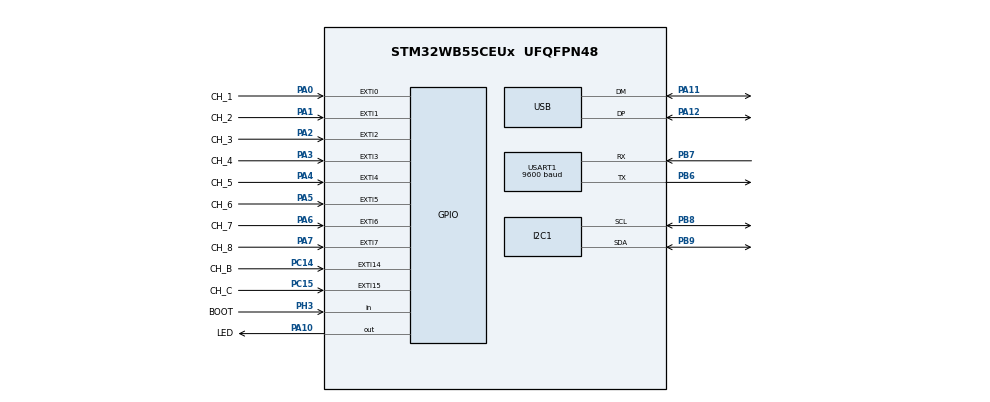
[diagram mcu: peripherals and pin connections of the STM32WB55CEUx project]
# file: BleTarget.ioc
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I2C1.OwnAddress=2
I2C1.Timing=0x10707DBC
Mcu.Family=STM32WB
Mcu.Name=STM32WB55CEUx
Mcu.Package=UFQFPN48
NVIC.EXTI0_IRQn=true\:0\:0\:false\:false\:true\:true\:true\:true
NVIC.EXTI15_10_IRQn=true\:0\:0\:true\:false\:true\:true\:true\:true
NVIC.EXTI1_IRQn=true\:0\:0\:false\:false\:true\:true\:true\:true
NVIC.EXTI2_IRQn=true\:0\:0\:false\:false\:true\:true\:true\:true
NVIC.EXTI3_IRQn=true\:0\:0\:false\:false\:true\:true\:true\:true
NVIC.EXTI4_IRQn=true\:0\:0\:false\:false\:true\:true\:true\:true
NVIC.EXTI9_5_IRQn=true\:0\:0\:false\:false\:true\:true\:true\:true
NVIC.HSEM_IRQn=true\:1\:0\:true\:false\:true\:false\:true\:true
NVIC.I2C1_ER_IRQn=true\:1\:0\:true\:false\:true\:true\:true\:true
NVIC.I2C1_EV_IRQn=true\:1\:0\:true\:false\:true\:true\:true\:true
NVIC.IPCC_C1_RX_IRQn=true\:1\:0\:true\:false\:true\:true\:true\:true
NVIC.IPCC_C1_TX_IRQn=true\:1\:0\:true\:false\:true\:true\:true\:true
NVIC.PriorityGroup=NVIC_PRIORITYGROUP_4
NVIC.TIM1_TRG_COM_TIM17_IRQn=true\:1\:0\:true\:false\:true\:true\:true\:true
NVIC.TIM1_UP_TIM16_IRQn=true\:15\:0\:false\:false\:true\:true\:true\:true
NVIC.TIM2_IRQn=true\:1\:0\:true\:false\:true\:true\:true\:true
NVIC.USART1_IRQn=true\:1\:0\:true\:false\:true\:true\:true\:true
NVIC.USB_LP_IRQn=true\:1\:0\:true\:false\:true\:false\:true\:true
OSC_IN.Mode=HSE-External-Oscillator
OSC_IN.Signal=RCC_OSC_IN
OSC_OUT.Mode=HSE-External-Oscillator
OSC_OUT.Signal=RCC_OSC_OUT
PA0.GPIO_Label=CH_1
PA0.Signal=GPXTI0
PA1.GPIO_Label=CH_2
PA1.Signal=GPXTI1
PA10.GPIO_Label=LED
PA10.GPIO_ModeDefaultOutputPP=GPIO_MODE_OUTPUT_OD
PA10.GPIO_PuPd=GPIO_NOPULL
PA10.GPIO_Speed=GPIO_SPEED_FREQ_MEDIUM
PA10.PinState=GPIO_PIN_SET
PA10.Signal=GPIO_Output
PA11.Mode=Device
PA11.Signal=USB_DM
PA12.Mode=Device
PA12.Signal=USB_DP
PA13.Mode=Trace_Asynchronous_SW
PA13.Signal=SYS_JTMS-SWDIO
PA14.Mode=Trace_Asynchronous_SW
PA14.Signal=SYS_JTCK-SWCLK
PA2.GPIO_Label=CH_3
PA2.Signal=GPXTI2
PA3.GPIO_Label=CH_4
PA3.Signal=GPXTI3
PA4.GPIO_Label=CH_5
PA4.Signal=GPXTI4
PA5.GPIO_Label=CH_6
PA5.Signal=GPXTI5
PA6.GPIO_Label=CH_7
PA6.Signal=GPXTI6
PA7.GPIO_Label=CH_8
PA7.Signal=GPXTI7
PB3.Mode=Trace_Asynchronous_SW
PB3.Signal=SYS_JTDO-SWO
PB6.Mode=Asynchronous
PB6.Signal=USART1_TX
PB7.Mode=Asynchronous
PB7.Signal=USART1_RX
PB8.Mode=I2C
PB8.Signal=I2C1_SCL
PB9.Mode=I2C
PB9.Signal=I2C1_SDA
PC14-OSC32_IN.GPIO_Label=CH_B
PC14-OSC32_IN.Signal=GPXTI14
PC15-OSC32_OUT.GPIO_Label=CH_C
PC15-OSC32_OUT.Signal=GPXTI15
PH3-BOOT0.GPIO_Label=BOOT
PH3-BOOT0.Signal=GPIO_Input
ProjectManager.HeapSize=0x200
ProjectManager.StackSize=0x400
ProjectManager.TargetToolchain=STM32CubeIDE
RCC.ADCFreq_Value=48000000
RCC.AHB2CLKDivider=RCC_SYSCLK_DIV2
RCC.AHBFreq_Value=64000000
RCC.APB1Freq_Value=64000000
RCC.APB1TimFreq_Value=64000000
RCC.APB2Freq_Value=64000000
RCC.APB2TimFreq_Value=64000000
RCC.APB3Freq_Value=16000000
RCC.CortexFreq_Value=64000000
RCC.HCLKFreq_Value=64000000
RCC.HSE_VALUE=32000000
RCC.HSI48_VALUE=48000000
RCC.HSI_VALUE=16000000
RCC.LSE_VALUE=32768
RCC.PLLN=32
RCC.PLLSAI1N=24
RCC.SYSCLKFreq_VALUE=64000000
RCC.SYSCLKSource=RCC_SYSCLKSOURCE_PLLCLK
RCC.USBFreq_Value=48000000
RCC.VCOOutputFreq_Value=128000000
RF1.Mode=RF1_Activate
RF1.Signal=RF_RF1
STM32_WPAN.AD_TYPE_COMPLETE_LOCAL_NAME=BLEtarget
STM32_WPAN.AD_TYPE_COMPLETE_LOCAL_NAME_LENGTH=10
STM32_WPAN.CFG_RTC_ASYNCH_PRESCALER=127
STM32_WPAN.CFG_RTC_SYNCH_PRESCALER=7812
STM32_WPAN.CFG_TX_POWER=(0x1F) /* 6dBm */
STM32_WPAN.CUSTOM_P2P_SERVER=Disabled
STM32_WPAN.CUSTOM_TEMPLATE=Enabled
STM32_WPAN.INCLUDE_AD_TYPE_COMPLETE_LOCAL_NAME=1
STM32_WPAN.NUMBER_OF_SERVICES=1
STM32_WPAN.PAIRING_PARAMETERS=OFF
STM32_WPAN.SERVICE1_CHAR1_GATT_NOTIFY_ATTRIBUTE_WRITE=\ 
STM32_WPAN.SERVICE1_CHAR1_GATT_NOTIFY_READ_REQ_AND_WAIT_FOR_APPL_RESP=\ 
STM32_WPAN.SERVICE1_CHAR1_GATT_NOTIFY_WRITE_REQ_AND_WAIT_FOR_APPL_RESP=\ 
STM32_WPAN.SERVICE1_CHAR1_LONG_NAME=X_position
STM32_WPAN.SERVICE1_CHAR1_PROP_NOTIFY=CHAR_PROP_NOTIFY
STM32_WPAN.SERVICE1_CHAR1_PROP_READ=CHAR_PROP_READ
STM32_WPAN.SERVICE1_CHAR1_SHORT_NAME=X
STM32_WPAN.SERVICE1_CHAR1_UUID=00 11
STM32_WPAN.SERVICE1_CHAR1_UUID_128_INPUT_TYPE=0
STM32_WPAN.SERVICE1_CHAR2_GATT_NOTIFY_ATTRIBUTE_WRITE=\ 
STM32_WPAN.SERVICE1_CHAR2_GATT_NOTIFY_READ_REQ_AND_WAIT_FOR_APPL_RESP=\ 
STM32_WPAN.SERVICE1_CHAR2_GATT_NOTIFY_WRITE_REQ_AND_WAIT_FOR_APPL_RESP=\ 
STM32_WPAN.SERVICE1_CHAR2_LONG_NAME=Y_position
STM32_WPAN.SERVICE1_CHAR2_PROP_NOTIFY=CHAR_PROP_NOTIFY
STM32_WPAN.SERVICE1_CHAR2_PROP_READ=CHAR_PROP_READ
STM32_WPAN.SERVICE1_CHAR2_SHORT_NAME=Y
STM32_WPAN.SERVICE1_CHAR2_UUID=00 12
STM32_WPAN.SERVICE1_LONG_NAME=Score
STM32_WPAN.SERVICE1_NUMBER_OF_CHARACTERISTICS=2
STM32_WPAN.SERVICE1_SHORT_NAME=Score
STM32_WPAN.SERVICE1_UUID=00 10
TIM16.Period=5999
TIM16.Prescaler=6399
TIM17.Period=20000
TIM17.Prescaler=6399
TIM2.Period=640000
USART1.BaudRate=9600
USART1.VirtualMode-Asynchronous=VM_ASYNC
USB_DEVICE.CLASS_NAME_FS=CDC
USB_DEVICE.PRODUCT_STRING_CDC_FS=STM32 Virtual ComPort
USB_DEVICE.USBD_MAX_NUM_CONFIGURATION=1
USB_DEVICE.USBD_MAX_NUM_INTERFACES=1
USB_DEVICE.VirtualMode=Cdc
USB_DEVICE.VirtualModeFS=Cdc_FS
VP_HSEM_VS_HSEM.Mode=HSEM_Activate
VP_IPCC_VS_IPCC.Mode=IPCC_Activate
VP_MEMORYMAP_VS_MEMORYMAP.Mode=CurAppReg
VP_RTC_VS_RTC_Activate.Mode=RTC_Enabled
VP_SEQUENCER_VS_SEQUENCER.Mode=SEQUENCER_Enabled
VP_STM32_WPAN_VS_BLE_HOST.Mode=STM32_WPAN_Enabled
VP_TIM16_VS_ClockSourceINT.Mode=Enable_Timer
VP_TIM17_VS_ClockSourceINT.Mode=Enable_Timer
VP_TIM2_VS_ClockSourceINT.Mode=Internal
VP_TINY_LPM_VS_TINY_LPM.Mode=TINY_LPM_Enabled
VP_USB_DEVICE_VS_USB_DEVICE_CDC_FS.Mode=CDC_FS
board=custom

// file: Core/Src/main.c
/* USER CODE BEGIN Header */
/**
  ******************************************************************************
  * @file           : main.c
  * @brief          : Main program body
  ******************************************************************************
  * @attention
  *
  * Copyright (c) 2024 STMicroelectronics.
  * All rights reserved.
  *
  * This software is licensed under terms that can be found in the LICENSE file
  * in the root directory of this software component.
  * If no LICENSE file comes with this software, it is provided AS-IS.
  *
  ******************************************************************************
  */
/* USER CODE END Header */
#include "main.h"
#include "usb_device.h"

/* USER CODE BEGIN Includes */
#include "app.h"
/* USER CODE END Includes */

I2C_HandleTypeDef hi2c1;

IPCC_HandleTypeDef hipcc;

RTC_HandleTypeDef hrtc;

UART_HandleTypeDef huart1;

void SystemClock_Config(void);
void PeriphCommonClock_Config(void);
static void MX_GPIO_Init(void);
static void MX_I2C1_Init(void);
static void MX_IPCC_Init(void);
static void MX_RTC_Init(void);
static void MX_USART1_UART_Init(void);
static void MX_TIM16_Init(void);
static void MX_TIM2_Init(void);
static void MX_TIM17_Init(void);
static void MX_RF_Init(void);

int main(void)
{

  /* USER CODE BEGIN 1 */
  //TIM_TypeDef *comTimer;   // 1ms timer used as timeout for com with other axis.

  /* USER CODE END 1 */

  /* MCU Configuration--------------------------------------------------------*/

  /* Reset of all peripherals, Initializes the Flash interface and the Systick. */
  HAL_Init();
  /* Config code for STM32_WPAN (HSE Tuning must be done before system clock configuration) */
  MX_APPE_Config();

  /* Configure the system clock */
  SystemClock_Config();

/* Configure the peripherals common clocks */
  PeriphCommonClock_Config();

  /* IPCC initialisation */
  MX_IPCC_Init();

  /* Initialize all configured peripherals */
  MX_GPIO_Init();
  MX_I2C1_Init();
  MX_RTC_Init();
  MX_USART1_UART_Init();
  MX_USB_Device_Init();
  MX_TIM16_Init();
  MX_TIM2_Init();
  MX_TIM17_Init();
  MX_RF_Init();
  /* USER CODE BEGIN 2 */
  app_init(&hi2c1, &huart1);
  /* USER CODE END 2 */

  /* Init code for STM32_WPAN */
  MX_APPE_Init();

  /* Infinite loop */
  while (1)
  {
    MX_APPE_Process();

    /* USER CODE BEGIN 3 */
    taskCyclic();
  }
  /* USER CODE END 3 */
}

void SystemClock_Config(void)
{
  RCC_OscInitTypeDef RCC_OscInitStruct = {0};
  RCC_ClkInitTypeDef RCC_ClkInitStruct = {0};

  /** Configure the main internal regulator output voltage
  */
  __HAL_PWR_VOLTAGESCALING_CONFIG(PWR_REGULATOR_VOLTAGE_SCALE1);

  /** Initializes the RCC Oscillators according to the specified parameters
  * in the RCC_OscInitTypeDef structure.
  */
  RCC_OscInitStruct.OscillatorType = RCC_OSCILLATORTYPE_HSI|RCC_OSCILLATORTYPE_LSI1
                              |RCC_OSCILLATORTYPE_HSE|RCC_OSCILLATORTYPE_LSE
                              |RCC_OSCILLATORTYPE_MSI;
  RCC_OscInitStruct.HSEState = RCC_HSE_ON;
  RCC_OscInitStruct.LSEState = RCC_LSE_OFF;
  RCC_OscInitStruct.HSIState = RCC_HSI_ON;
  RCC_OscInitStruct.MSIState = RCC_MSI_ON;
  RCC_OscInitStruct.HSICalibrationValue = RCC_HSICALIBRATION_DEFAULT;
  RCC_OscInitStruct.MSICalibrationValue = RCC_MSICALIBRATION_DEFAULT;
  RCC_OscInitStruct.MSIClockRange = RCC_MSIRANGE_6;
  RCC_OscInitStruct.LSIState = RCC_LSI_ON;
  RCC_OscInitStruct.PLL.PLLState = RCC_PLL_ON;
  RCC_OscInitStruct.PLL.PLLSource = RCC_PLLSOURCE_MSI;
  RCC_OscInitStruct.PLL.PLLM = RCC_PLLM_DIV1;
  RCC_OscInitStruct.PLL.PLLN = 32;
  RCC_OscInitStruct.PLL.PLLP = RCC_PLLP_DIV2;
  RCC_OscInitStruct.PLL.PLLR = RCC_PLLR_DIV2;
  RCC_OscInitStruct.PLL.PLLQ = RCC_PLLQ_DIV2;
  if (HAL_RCC_OscConfig(&RCC_OscInitStruct) != HAL_OK)
  {
    Error_Handler();
  }

  /** Configure the SYSCLKSource, HCLK, PCLK1 and PCLK2 clocks dividers
  */
  RCC_ClkInitStruct.ClockType = RCC_CLOCKTYPE_HCLK4|RCC_CLOCKTYPE_HCLK2
                              |RCC_CLOCKTYPE_HCLK|RCC_CLOCKTYPE_SYSCLK
                              |RCC_CLOCKTYPE_PCLK1|RCC_CLOCKTYPE_PCLK2;
  RCC_ClkInitStruct.SYSCLKSource = RCC_SYSCLKSOURCE_PLLCLK;
  RCC_ClkInitStruct.AHBCLKDivider = RCC_SYSCLK_DIV1;
  RCC_ClkInitStruct.APB1CLKDivider = RCC_HCLK_DIV1;
  RCC_ClkInitStruct.APB2CLKDivider = RCC_HCLK_DIV1;
  RCC_ClkInitStruct.AHBCLK2Divider = RCC_SYSCLK_DIV2;
  RCC_ClkInitStruct.AHBCLK4Divider = RCC_SYSCLK_DIV1;

  if (HAL_RCC_ClockConfig(&RCC_ClkInitStruct, FLASH_LATENCY_3) != HAL_OK)
  {
    Error_Handler();
  }

  /** Enable MSI Auto calibration
  */
  HAL_RCCEx_EnableMSIPLLMode();
}

void PeriphCommonClock_Config(void)
{
  RCC_PeriphCLKInitTypeDef PeriphClkInitStruct = {0};

  /** Initializes the peripherals clock
  */
  PeriphClkInitStruct.PeriphClockSelection = RCC_PERIPHCLK_SMPS|RCC_PERIPHCLK_RFWAKEUP;
  PeriphClkInitStruct.RFWakeUpClockSelection = RCC_RFWKPCLKSOURCE_HSE_DIV1024;
  PeriphClkInitStruct.SmpsClockSelection = RCC_SMPSCLKSOURCE_HSI;
  PeriphClkInitStruct.SmpsDivSelection = RCC_SMPSCLKDIV_RANGE1;

  if (HAL_RCCEx_PeriphCLKConfig(&PeriphClkInitStruct) != HAL_OK)
  {
    Error_Handler();
  }
  /* USER CODE BEGIN Smps */
  LL_HSEM_1StepLock( HSEM, 5 ); // Fix to make USB work with BLE.
  /* USER CODE END Smps */
}

static void MX_I2C1_Init(void)
{

  hi2c1.Instance = I2C1;
  hi2c1.Init.Timing = 0x10707DBC;
  hi2c1.Init.OwnAddress1 = 4;
  hi2c1.Init.AddressingMode = I2C_ADDRESSINGMODE_7BIT;
  hi2c1.Init.DualAddressMode = I2C_DUALADDRESS_DISABLE;
  hi2c1.Init.OwnAddress2 = 0;
  hi2c1.Init.OwnAddress2Masks = I2C_OA2_NOMASK;
  hi2c1.Init.GeneralCallMode = I2C_GENERALCALL_DISABLE;
  hi2c1.Init.NoStretchMode = I2C_NOSTRETCH_DISABLE;
  if (HAL_I2C_Init(&hi2c1) != HAL_OK)
  {
    Error_Handler();
  }

  /** Configure Analogue filter
  */
  if (HAL_I2CEx_ConfigAnalogFilter(&hi2c1, I2C_ANALOGFILTER_ENABLE) != HAL_OK)
  {
    Error_Handler();
  }

  /** Configure Digital filter
  */
  if (HAL_I2CEx_ConfigDigitalFilter(&hi2c1, 0) != HAL_OK)
  {
    Error_Handler();
  }

}

static void MX_IPCC_Init(void)
{

  hipcc.Instance = IPCC;
  if (HAL_IPCC_Init(&hipcc) != HAL_OK)
  {
    Error_Handler();
  }

}

static void MX_RF_Init(void)
{

}

static void MX_RTC_Init(void)
{

  /** Initialize RTC Only
  */
  hrtc.Instance = RTC;
  hrtc.Init.HourFormat = RTC_HOURFORMAT_24;
  hrtc.Init.AsynchPrediv = CFG_RTC_ASYNCH_PRESCALER;
  hrtc.Init.SynchPrediv = CFG_RTC_SYNCH_PRESCALER;
  hrtc.Init.OutPut = RTC_OUTPUT_DISABLE;
  hrtc.Init.OutPutPolarity = RTC_OUTPUT_POLARITY_HIGH;
  hrtc.Init.OutPutType = RTC_OUTPUT_TYPE_OPENDRAIN;
  hrtc.Init.OutPutRemap = RTC_OUTPUT_REMAP_NONE;
  if (HAL_RTC_Init(&hrtc) != HAL_OK)
  {
    Error_Handler();
  }

}

static void MX_TIM2_Init(void)
{

  LL_TIM_InitTypeDef TIM_InitStruct = {0};

  /* Peripheral clock enable */
  LL_APB1_GRP1_EnableClock(LL_APB1_GRP1_PERIPH_TIM2);

  /* TIM2 interrupt Init */
  NVIC_SetPriority(TIM2_IRQn, NVIC_EncodePriority(NVIC_GetPriorityGrouping(),1, 0));
  NVIC_EnableIRQ(TIM2_IRQn);

  TIM_InitStruct.Prescaler = 0;
  TIM_InitStruct.CounterMode = LL_TIM_COUNTERMODE_UP;
  TIM_InitStruct.Autoreload = 640000;
  TIM_InitStruct.ClockDivision = LL_TIM_CLOCKDIVISION_DIV1;
  LL_TIM_Init(TIM2, &TIM_InitStruct);
  LL_TIM_SetClockSource(TIM2, LL_TIM_CLOCKSOURCE_INTERNAL);
  LL_TIM_SetTriggerOutput(TIM2, LL_TIM_TRGO_RESET);
  LL_TIM_DisableMasterSlaveMode(TIM2);

}

static void MX_TIM16_Init(void)
{

  LL_TIM_InitTypeDef TIM_InitStruct = {0};

  /* Peripheral clock enable */
  LL_APB2_GRP1_EnableClock(LL_APB2_GRP1_PERIPH_TIM16);

  /* TIM16 interrupt Init */
  NVIC_SetPriority(TIM1_UP_TIM16_IRQn, NVIC_EncodePriority(NVIC_GetPriorityGrouping(),15, 0));
  NVIC_EnableIRQ(TIM1_UP_TIM16_IRQn);

  TIM_InitStruct.Prescaler = 6399;
  TIM_InitStruct.CounterMode = LL_TIM_COUNTERMODE_UP;
  TIM_InitStruct.Autoreload = 5999;
  TIM_InitStruct.ClockDivision = LL_TIM_CLOCKDIVISION_DIV1;
  TIM_InitStruct.RepetitionCounter = 0;
  LL_TIM_Init(TIM16, &TIM_InitStruct);
  LL_TIM_DisableARRPreload(TIM16);

}

static void MX_TIM17_Init(void)
{

  LL_TIM_InitTypeDef TIM_InitStruct = {0};

  /* Peripheral clock enable */
  LL_APB2_GRP1_EnableClock(LL_APB2_GRP1_PERIPH_TIM17);

  /* TIM17 interrupt Init */
  NVIC_SetPriority(TIM1_TRG_COM_TIM17_IRQn, NVIC_EncodePriority(NVIC_GetPriorityGrouping(),1, 0));
  NVIC_EnableIRQ(TIM1_TRG_COM_TIM17_IRQn);

  TIM_InitStruct.Prescaler = 6399;
  TIM_InitStruct.CounterMode = LL_TIM_COUNTERMODE_UP;
  TIM_InitStruct.Autoreload = 20000;
  TIM_InitStruct.ClockDivision = LL_TIM_CLOCKDIVISION_DIV1;
  TIM_InitStruct.RepetitionCounter = 0;
  LL_TIM_Init(TIM17, &TIM_InitStruct);
  LL_TIM_DisableARRPreload(TIM17);

}

static void MX_USART1_UART_Init(void)
{

  huart1.Instance = USART1;
  huart1.Init.BaudRate = 9600;
  huart1.Init.WordLength = UART_WORDLENGTH_8B;
  huart1.Init.StopBits = UART_STOPBITS_1;
  huart1.Init.Parity = UART_PARITY_NONE;
  huart1.Init.Mode = UART_MODE_TX_RX;
  huart1.Init.HwFlowCtl = UART_HWCONTROL_NONE;
  huart1.Init.OverSampling = UART_OVERSAMPLING_16;
  huart1.Init.OneBitSampling = UART_ONE_BIT_SAMPLE_DISABLE;
  huart1.Init.ClockPrescaler = UART_PRESCALER_DIV1;
  huart1.AdvancedInit.AdvFeatureInit = UART_ADVFEATURE_NO_INIT;
  if (HAL_UART_Init(&huart1) != HAL_OK)
  {
    Error_Handler();
  }
  if (HAL_UARTEx_SetTxFifoThreshold(&huart1, UART_TXFIFO_THRESHOLD_1_8) != HAL_OK)
  {
    Error_Handler();
  }
  if (HAL_UARTEx_SetRxFifoThreshold(&huart1, UART_RXFIFO_THRESHOLD_1_8) != HAL_OK)
  {
    Error_Handler();
  }
  if (HAL_UARTEx_DisableFifoMode(&huart1) != HAL_OK)
  {
    Error_Handler();
  }

}

static void MX_GPIO_Init(void)
{
  GPIO_InitTypeDef GPIO_InitStruct = {0};

  /* GPIO Ports Clock Enable */
  __HAL_RCC_GPIOC_CLK_ENABLE();
  __HAL_RCC_GPIOH_CLK_ENABLE();
  __HAL_RCC_GPIOB_CLK_ENABLE();
  __HAL_RCC_GPIOA_CLK_ENABLE();

  /*Configure GPIO pin Output Level */
  HAL_GPIO_WritePin(LED_GPIO_Port, LED_Pin, GPIO_PIN_SET);

  /*Configure GPIO pins : CH_B_Pin CH_C_Pin */
  GPIO_InitStruct.Pin = CH_B_Pin|CH_C_Pin;
  GPIO_InitStruct.Mode = GPIO_MODE_IT_RISING;
  GPIO_InitStruct.Pull = GPIO_NOPULL;
  HAL_GPIO_Init(GPIOC, &GPIO_InitStruct);

  /*Configure GPIO pin : BOOT_Pin */
  GPIO_InitStruct.Pin = BOOT_Pin;
  GPIO_InitStruct.Mode = GPIO_MODE_INPUT;
  GPIO_InitStruct.Pull = GPIO_NOPULL;
  HAL_GPIO_Init(BOOT_GPIO_Port, &GPIO_InitStruct);

  /*Configure GPIO pins : CH_1_Pin CH_2_Pin CH_3_Pin CH_4_Pin
                           CH_5_Pin CH_6_Pin CH_7_Pin CH_8_Pin */
  GPIO_InitStruct.Pin = CH_1_Pin|CH_2_Pin|CH_3_Pin|CH_4_Pin
                          |CH_5_Pin|CH_6_Pin|CH_7_Pin|CH_8_Pin;
  GPIO_InitStruct.Mode = GPIO_MODE_IT_RISING;
  GPIO_InitStruct.Pull = GPIO_NOPULL;
  HAL_GPIO_Init(GPIOA, &GPIO_InitStruct);

  /*Configure GPIO pin : LED_Pin */
  GPIO_InitStruct.Pin = LED_Pin;
  GPIO_InitStruct.Mode = GPIO_MODE_OUTPUT_OD;
  GPIO_InitStruct.Pull = GPIO_NOPULL;
  GPIO_InitStruct.Speed = GPIO_SPEED_FREQ_MEDIUM;
  HAL_GPIO_Init(LED_GPIO_Port, &GPIO_InitStruct);

  /* EXTI interrupt init*/
  HAL_NVIC_SetPriority(EXTI0_IRQn, 0, 0);
  HAL_NVIC_EnableIRQ(EXTI0_IRQn);

  HAL_NVIC_SetPriority(EXTI1_IRQn, 0, 0);
  HAL_NVIC_EnableIRQ(EXTI1_IRQn);

  HAL_NVIC_SetPriority(EXTI2_IRQn, 0, 0);
  HAL_NVIC_EnableIRQ(EXTI2_IRQn);

  HAL_NVIC_SetPriority(EXTI3_IRQn, 0, 0);
  HAL_NVIC_EnableIRQ(EXTI3_IRQn);

  HAL_NVIC_SetPriority(EXTI4_IRQn, 0, 0);
  HAL_NVIC_EnableIRQ(EXTI4_IRQn);

  HAL_NVIC_SetPriority(EXTI9_5_IRQn, 0, 0);
  HAL_NVIC_EnableIRQ(EXTI9_5_IRQn);

  HAL_NVIC_SetPriority(EXTI15_10_IRQn, 0, 0);
  HAL_NVIC_EnableIRQ(EXTI15_10_IRQn);

}

void Error_Handler(void)
{
  __disable_irq();
  while (1)
  {
  }
}
